AUTOSAR XML (schema 4-3-0)
package /ComponentTypes
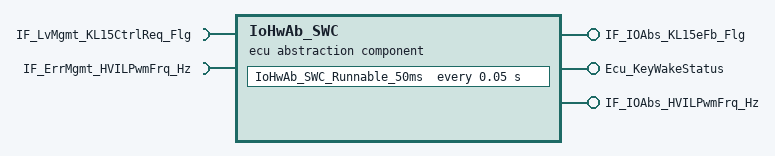
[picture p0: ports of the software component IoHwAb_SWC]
  ecu abstraction sw component type IoHwAb_SWC
    require port IF_LvMgmt_KL15CtrlReq_Flg: nonqueued-receiver-com-spec=data-element=tec_LvMgmt_KL15CtrlReq_Flg, required-interface=IF_LvMgmt_KL15CtrlReq_Flg
    provide port IF_IOAbs_KL15eFb_Flg: nonqueued-sender-com-spec=tec_IOAbs_KL15eFb_Flg, provided-interface=IF_IOAbs_KL15eFb_Flg
    provide port Ecu_KeyWakeStatus: nonqueued-sender-com-spec=Keywake, provided-interface=Ecu_KeyWakeStatus
    provide port IF_IOAbs_HVILPwmFrq_Hz: nonqueued-sender-com-spec=tec_IOAbs_HVILPwmFrq_Hz, provided-interface=IF_IOAbs_HVILPwmFrq_Hz
    require port IF_ErrMgmt_HVILPwmFrq_Hz: nonqueued-receiver-com-spec=data-element=tec_ErrMgmt_HVILPwmFrq_Hz, required-interface=IF_ErrMgmt_HVILPwmFrq_Hz
    behavior IoHwAb_SWC_InternalBehavior
      timing event TMT_IoHwAb_SWC_Runnable_50ms: start-on-event=IoHwAb_SWC_Runnable_50ms, period=0.05
      runnable IoHwAb_SWC_Runnable_50ms
        data-receive-point-by-arguments:
          access REC_IF_LvMgmt_KL15CtrlReq_Flg_tec_LvMgmt_KL15CtrlReq_Flg: accessed-variable=IF_LvMgmt_KL15CtrlReq_Flg.tec_LvMgmt_KL15CtrlReq_Flg
          access REC_IF_ErrMgmt_HVILPwmFrq_Hz_tec_ErrMgmt_HVILPwmFrq_Hz: accessed-variable=IF_ErrMgmt_HVILPwmFrq_Hz.tec_ErrMgmt_HVILPwmFrq_Hz
        data-send-points:
          access SEND_IF_IOAbs_KL15eFb_Flg_tec_IOAbs_KL15eFb_Flg: accessed-variable=IF_IOAbs_KL15eFb_Flg.tec_IOAbs_KL15eFb_Flg
          access SEND_Ecu_KeyWakeStatus_Keywake: accessed-variable=Ecu_KeyWakeStatus.Keywake
          access SEND_IF_IOAbs_HVILPwmFrq_Hz_tec_IOAbs_HVILPwmFrq_Hz: accessed-variable=IF_IOAbs_HVILPwmFrq_Hz.tec_IOAbs_HVILPwmFrq_Hz
  swc implementation IoHwAb_SWC_Implementation: behavior=IoHwAb_SWC_InternalBehavior
